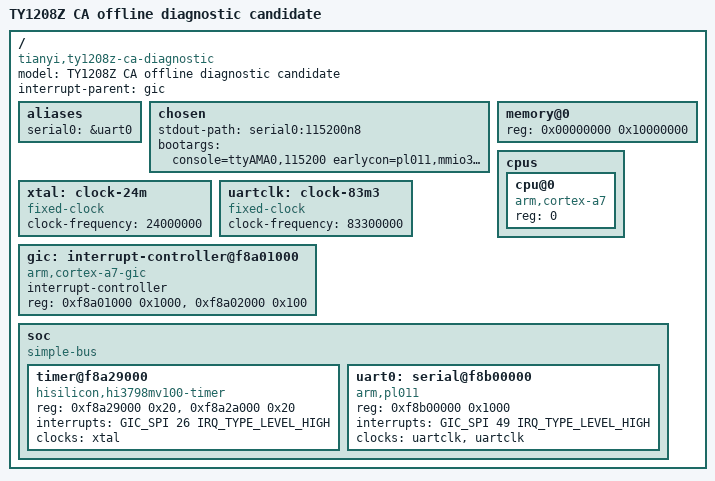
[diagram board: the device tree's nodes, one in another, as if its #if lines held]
// SPDX-License-Identifier: GPL-2.0-only
/dts-v1/;

/* getinfo ddrfree starts at 16 MiB. Keep the lower range out of allocation;
 * the ARM kernel itself decompresses below it, as in the existing boot path.
 */
/memreserve/ 0x00000000 0x01000000;
#ifdef TY1208Z_FULL_MEMORY
#include "hi3798mv100-ty1208z-loader-reservations.dtsi"
#endif
#include <dt-bindings/interrupt-controller/arm-gic.h>

/*
 * OFFLINE CANDIDATE, NOT A VERIFIED BOARD DESCRIPTION.
 * Register addresses, IRQs and fixed clocks follow the local Hinas DTB and
 * pinned vendor reference. RAM size and secure reservations must be checked
 * against the actual machine BEFORE any RAM boot is attempted.
 */
/ {
	model = "TY1208Z CA offline diagnostic candidate";
	compatible = "tianyi,ty1208z-ca-diagnostic", "hi3798mv100-series";
	#address-cells = <1>;
	#size-cells = <1>;
	interrupt-parent = <&gic>;

	aliases { serial0 = &uart0; };

	chosen {
		stdout-path = "serial0:115200n8";
		bootargs = "console=ttyAMA0,115200 earlycon=pl011,mmio32,0xf8b00000 rdinit=/init loglevel=8 ignore_loglevel keep_bootcon panic=0";
	};

	/* Restrict diagnosis to low 256 MiB of the measured 1 GiB DDR. This
	 * excludes all observed high boot allocations; it is not an OTP map.
	 */
	memory@0 {
		device_type = "memory";
		reg = <0x00000000 0x10000000>;
	};

	cpus {
		#address-cells = <1>;
		#size-cells = <0>;
		cpu@0 {
			device_type = "cpu";
			compatible = "arm,cortex-a7";
			reg = <0>;
		};
	};

	xtal: clock-24m {
		compatible = "fixed-clock";
		#clock-cells = <0>;
		clock-frequency = <24000000>;
	};
	uartclk: clock-83m3 {
		compatible = "fixed-clock";
		#clock-cells = <0>;
		clock-frequency = <83300000>;
	};

	gic: interrupt-controller@f8a01000 {
		compatible = "arm,cortex-a7-gic";
		#interrupt-cells = <3>;
		#address-cells = <0>;
		interrupt-controller;
		reg = <0xf8a01000 0x1000>, <0xf8a02000 0x100>;
	};

	soc {
		compatible = "simple-bus";
		#address-cells = <1>;
		#size-cells = <1>;
		ranges;

		/* Original clocksource and CPU0 event counters, not CPU1's counter. */
		timer@f8a29000 {
			compatible = "hisilicon,hi3798mv100-timer";
			reg = <0xf8a29000 0x20>, <0xf8a2a000 0x20>;
			reg-names = "clocksource", "clockevent";
			interrupts = <GIC_SPI 26 IRQ_TYPE_LEVEL_HIGH>;
			clocks = <&xtal>;
		};

		uart0: serial@f8b00000 {
			compatible = "arm,pl011", "arm,primecell";
			reg = <0xf8b00000 0x1000>;
			interrupts = <GIC_SPI 49 IRQ_TYPE_LEVEL_HIGH>;
			clocks = <&uartclk>, <&uartclk>;
			clock-names = "uartclk", "apb_pclk";
		};
	};
};
